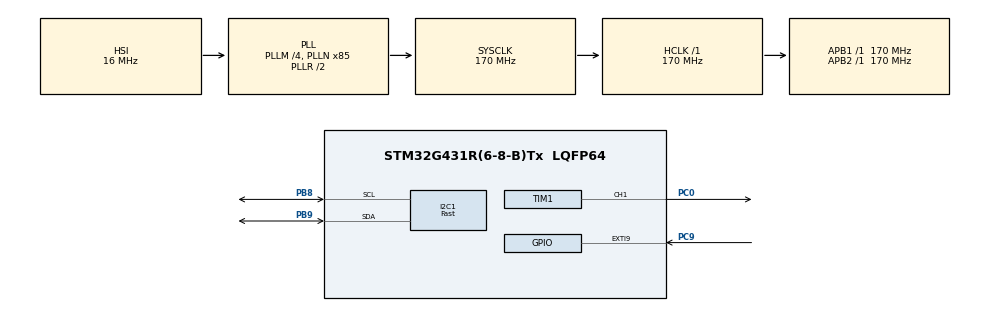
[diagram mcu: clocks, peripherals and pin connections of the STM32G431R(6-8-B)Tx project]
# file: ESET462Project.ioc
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Dma.I2C1_RX.0.Direction=DMA_PERIPH_TO_MEMORY
Dma.I2C1_RX.0.EventEnable=DISABLE
Dma.I2C1_RX.0.Instance=DMA1_Channel1
Dma.I2C1_RX.0.MemDataAlignment=DMA_MDATAALIGN_BYTE
Dma.I2C1_RX.0.MemInc=DMA_MINC_ENABLE
Dma.I2C1_RX.0.Mode=DMA_NORMAL
Dma.I2C1_RX.0.PeriphDataAlignment=DMA_PDATAALIGN_BYTE
Dma.I2C1_RX.0.PeriphInc=DMA_PINC_DISABLE
Dma.I2C1_RX.0.Polarity=HAL_DMAMUX_REQ_GEN_RISING
Dma.I2C1_RX.0.Priority=DMA_PRIORITY_LOW
Dma.I2C1_RX.0.RequestNumber=1
Dma.I2C1_RX.0.SignalID=NONE
Dma.I2C1_RX.0.SyncEnable=DISABLE
Dma.I2C1_RX.0.SyncPolarity=HAL_DMAMUX_SYNC_NO_EVENT
Dma.I2C1_RX.0.SyncRequestNumber=1
Dma.I2C1_RX.0.SyncSignalID=NONE
Dma.Request0=I2C1_RX
FREERTOS.Tasks01=defaultTask,24,128,StartDefaultTask,Default,NULL,Dynamic,NULL,NULL
FREERTOS.configCHECK_FOR_STACK_OVERFLOW=2
FREERTOS.configTOTAL_HEAP_SIZE=8192
FREERTOS.configUSE_MALLOC_FAILED_HOOK=1
I2C1.I2C_Speed_Mode=I2C_Fast
I2C1.Timing=0x40621236
Mcu.Family=STM32G4
Mcu.Name=STM32G431R(6-8-B)Tx
Mcu.Package=LQFP64
NUCLEO-G431RB.BUTTON=1
NUCLEO-G431RB.LD1=true
NUCLEO-G431RB.VCP=true
NVIC.DMA1_Channel1_IRQn=true\:5\:0\:false\:false\:true\:true\:false\:true\:true
NVIC.EXTI15_10_IRQn=true\:5\:0\:false\:false\:true\:true\:false\:true\:true
NVIC.EXTI9_5_IRQn=true\:5\:0\:false\:false\:true\:true\:true\:true\:true
NVIC.I2C1_ER_IRQn=true\:5\:0\:false\:false\:true\:true\:true\:true\:true
NVIC.I2C1_EV_IRQn=true\:5\:0\:false\:false\:true\:true\:true\:true\:true
NVIC.PriorityGroup=NVIC_PRIORITYGROUP_4
NVIC.TIM6_DAC_IRQn=true\:15\:0\:false\:false\:true\:false\:false\:true\:true
NVIC.TimeBase=TIM6_DAC_IRQn
NVIC.TimeBaseIP=TIM6
PA13.GPIO_Label=T_SWDIO
PA13.Mode=Serial_Wire
PA13.Signal=SYS_JTMS-SWDIO
PA14.GPIO_Label=T_SWCLK
PA14.Mode=Serial_Wire
PA14.Signal=SYS_JTCK-SWCLK
PA2.Signal=LPUART1_TX
PA3.Signal=LPUART1_RX
PB3.GPIO_Label=T_SWO
PB3.Signal=SYS_JTDO-SWO
PB8-BOOT0.Mode=I2C
PB8-BOOT0.Signal=I2C1_SCL
PB9.Mode=I2C
PB9.Signal=I2C1_SDA
PC0.Signal=S_TIM1_CH1
PC14-OSC32_IN.GPIO_Label=RCC_OSC32_OUT
PC14-OSC32_IN.Signal=RCC_OSC32_IN
PC15-OSC32_OUT.GPIO_Label=RCC_OSC32_OUT
PC15-OSC32_OUT.Signal=RCC_OSC32_OUT
PC9.Signal=GPXTI9
PF0-OSC_IN.GPIO_Label=RCC_OSC_IN
PF0-OSC_IN.Signal=RCC_OSC_IN
PF1-OSC_OUT.GPIO_Label=RCC_OSC_OUT
PF1-OSC_OUT.Signal=RCC_OSC_OUT
ProjectManager.HeapSize=0x200
ProjectManager.StackSize=0x400
ProjectManager.TargetToolchain=CMake
RCC.ADC12Freq_Value=170000000
RCC.AHBFreq_Value=170000000
RCC.APB1Freq_Value=170000000
RCC.APB1TimFreq_Value=170000000
RCC.APB2Freq_Value=170000000
RCC.APB2TimFreq_Value=170000000
RCC.CortexFreq_Value=170000000
RCC.EXTERNAL_CLOCK_VALUE=12288000
RCC.HCLKFreq_Value=170000000
RCC.HSE_VALUE=24000000
RCC.HSI48_VALUE=48000000
RCC.HSI_VALUE=16000000
RCC.LSE_VALUE=32768
RCC.PLLM=RCC_PLLM_DIV4
RCC.PLLN=85
RCC.RTCClockSelection=RCC_RTCCLKSOURCE_LSE
RCC.SYSCLKFreq_VALUE=170000000
RCC.SYSCLKSource=RCC_SYSCLKSOURCE_PLLCLK
RCC.USBFreq_Value=170000000
RCC.VCOOutputFreq_Value=340000000
SH.S_TIM1_CH1.0=TIM1_CH1,PWM Generation1 CH1
TIM1.AutoReloadPreload=TIM_AUTORELOAD_PRELOAD_ENABLE
TIM1.Channel-PWM\ Generation1\ CH1=TIM_CHANNEL_1
TIM1.PeriodNoDither=19999
TIM1.Prescaler=169
TIM1.PulseNoDither_1=1000
VP_FREERTOS_VS_CMSIS_V2.Mode=CMSIS_V2
VP_NUCLEO-G431RB_VS_BSP_COMMON.Mode=COMMON
VP_SYS_VS_DBSignals.Mode=DisableDeadBatterySignals
VP_SYS_VS_tim6.Mode=TIM6
VP_TIM1_VS_ClockSourceINT.Mode=Internal
board=NUCLEO-G431RB

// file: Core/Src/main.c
/* USER CODE BEGIN Header */
/**
  ******************************************************************************
  * @file           : main.c
  * @brief          : Main program body
  ******************************************************************************
  * @attention
  *
  * Copyright (c) 2026 STMicroelectronics.
  * All rights reserved.
  *
  * This software is licensed under terms that can be found in the LICENSE file
  * in the root directory of this software component.
  * If no LICENSE file comes with this software, it is provided AS-IS.
  *
  ******************************************************************************
  */
/* USER CODE END Header */
#include "main.h"
#include "cmsis_os.h"

/* USER CODE BEGIN Includes */
#include "controls.h"
/* USER CODE END Includes */

COM_InitTypeDef BspCOMInit;
I2C_HandleTypeDef hi2c1;
DMA_HandleTypeDef hdma_i2c1_rx;

TIM_HandleTypeDef htim1;

/* Definitions for defaultTask */
osThreadId_t defaultTaskHandle;
const osThreadAttr_t defaultTask_attributes = {
  .name = "defaultTask",
  .priority = (osPriority_t) osPriorityNormal,
  .stack_size = 128 * 4
};

void SystemClock_Config(void);
static void MX_GPIO_Init(void);
static void MX_DMA_Init(void);
static void MX_I2C1_Init(void);
static void MX_TIM1_Init(void);
void StartDefaultTask(void *argument);

int main(void)
{

  /* MCU Configuration--------------------------------------------------------*/

  /* Reset of all peripherals, Initializes the Flash interface and the Systick. */
  HAL_Init();

  /* Configure the system clock */
  SystemClock_Config();

  /* Initialize all configured peripherals */
  MX_GPIO_Init();
  MX_DMA_Init();
  MX_I2C1_Init();
  MX_TIM1_Init();
  /* USER CODE BEGIN 2 */
  Controls_Init(&hi2c1, &htim1, TIM_CHANNEL_1);
  /* USER CODE END 2 */

  /* Init scheduler */
  osKernelInitialize();

  /* Create the thread(s) */
  /* creation of defaultTask */
  defaultTaskHandle = osThreadNew(StartDefaultTask, NULL, &defaultTask_attributes);

  /* USER CODE BEGIN RTOS_THREADS */
  Controls_StartTask();
  /* USER CODE END RTOS_THREADS */

  /* Initialize leds */
  BSP_LED_Init(LED_GREEN);

  /* Initialize USER push-button, will be used to trigger an interrupt each time it's pressed.*/
  BSP_PB_Init(BUTTON_USER, BUTTON_MODE_EXTI);

  /* Initialize COM1 port (115200, 8 bits (7-bit data + 1 stop bit), no parity */
  BspCOMInit.BaudRate   = 115200;
  BspCOMInit.WordLength = COM_WORDLENGTH_8B;
  BspCOMInit.StopBits   = COM_STOPBITS_1;
  BspCOMInit.Parity     = COM_PARITY_NONE;
  BspCOMInit.HwFlowCtl  = COM_HWCONTROL_NONE;
  if (BSP_COM_Init(COM1, &BspCOMInit) != BSP_ERROR_NONE)
  {
    Error_Handler();
  }

  /* Start scheduler */
  osKernelStart();

  /* We should never get here as control is now taken by the scheduler */

  /* Infinite loop */
    while (1)
    {

    }
}

void SystemClock_Config(void)
{
  RCC_OscInitTypeDef RCC_OscInitStruct = {0};
  RCC_ClkInitTypeDef RCC_ClkInitStruct = {0};

  /** Configure the main internal regulator output voltage
  */
  HAL_PWREx_ControlVoltageScaling(PWR_REGULATOR_VOLTAGE_SCALE1_BOOST);

  /** Initializes the RCC Oscillators according to the specified parameters
  * in the RCC_OscInitTypeDef structure.
  */
  RCC_OscInitStruct.OscillatorType = RCC_OSCILLATORTYPE_HSI;
  RCC_OscInitStruct.HSIState = RCC_HSI_ON;
  RCC_OscInitStruct.HSICalibrationValue = RCC_HSICALIBRATION_DEFAULT;
  RCC_OscInitStruct.PLL.PLLState = RCC_PLL_ON;
  RCC_OscInitStruct.PLL.PLLSource = RCC_PLLSOURCE_HSI;
  RCC_OscInitStruct.PLL.PLLM = RCC_PLLM_DIV4;
  RCC_OscInitStruct.PLL.PLLN = 85;
  RCC_OscInitStruct.PLL.PLLP = RCC_PLLP_DIV2;
  RCC_OscInitStruct.PLL.PLLQ = RCC_PLLQ_DIV2;
  RCC_OscInitStruct.PLL.PLLR = RCC_PLLR_DIV2;
  if (HAL_RCC_OscConfig(&RCC_OscInitStruct) != HAL_OK)
  {
    Error_Handler();
  }

  /** Initializes the CPU, AHB and APB buses clocks
  */
  RCC_ClkInitStruct.ClockType = RCC_CLOCKTYPE_HCLK|RCC_CLOCKTYPE_SYSCLK
                              |RCC_CLOCKTYPE_PCLK1|RCC_CLOCKTYPE_PCLK2;
  RCC_ClkInitStruct.SYSCLKSource = RCC_SYSCLKSOURCE_PLLCLK;
  RCC_ClkInitStruct.AHBCLKDivider = RCC_SYSCLK_DIV1;
  RCC_ClkInitStruct.APB1CLKDivider = RCC_HCLK_DIV1;
  RCC_ClkInitStruct.APB2CLKDivider = RCC_HCLK_DIV1;

  if (HAL_RCC_ClockConfig(&RCC_ClkInitStruct, FLASH_LATENCY_4) != HAL_OK)
  {
    Error_Handler();
  }
}

static void MX_I2C1_Init(void)
{

  hi2c1.Instance = I2C1;
  hi2c1.Init.Timing = 0x40621236;
  hi2c1.Init.OwnAddress1 = 0;
  hi2c1.Init.AddressingMode = I2C_ADDRESSINGMODE_7BIT;
  hi2c1.Init.DualAddressMode = I2C_DUALADDRESS_DISABLE;
  hi2c1.Init.OwnAddress2 = 0;
  hi2c1.Init.OwnAddress2Masks = I2C_OA2_NOMASK;
  hi2c1.Init.GeneralCallMode = I2C_GENERALCALL_DISABLE;
  hi2c1.Init.NoStretchMode = I2C_NOSTRETCH_DISABLE;
  if (HAL_I2C_Init(&hi2c1) != HAL_OK)
  {
    Error_Handler();
  }

  /** Configure Analogue filter
  */
  if (HAL_I2CEx_ConfigAnalogFilter(&hi2c1, I2C_ANALOGFILTER_ENABLE) != HAL_OK)
  {
    Error_Handler();
  }

  /** Configure Digital filter
  */
  if (HAL_I2CEx_ConfigDigitalFilter(&hi2c1, 0) != HAL_OK)
  {
    Error_Handler();
  }

}

static void MX_TIM1_Init(void)
{

  TIM_ClockConfigTypeDef sClockSourceConfig = {0};
  TIM_MasterConfigTypeDef sMasterConfig = {0};
  TIM_OC_InitTypeDef sConfigOC = {0};
  TIM_BreakDeadTimeConfigTypeDef sBreakDeadTimeConfig = {0};

  htim1.Instance = TIM1;
  htim1.Init.Prescaler = 169;
  htim1.Init.CounterMode = TIM_COUNTERMODE_UP;
  htim1.Init.Period = 19999;
  htim1.Init.ClockDivision = TIM_CLOCKDIVISION_DIV1;
  htim1.Init.RepetitionCounter = 0;
  htim1.Init.AutoReloadPreload = TIM_AUTORELOAD_PRELOAD_ENABLE;
  if (HAL_TIM_Base_Init(&htim1) != HAL_OK)
  {
    Error_Handler();
  }
  sClockSourceConfig.ClockSource = TIM_CLOCKSOURCE_INTERNAL;
  if (HAL_TIM_ConfigClockSource(&htim1, &sClockSourceConfig) != HAL_OK)
  {
    Error_Handler();
  }
  if (HAL_TIM_PWM_Init(&htim1) != HAL_OK)
  {
    Error_Handler();
  }
  sMasterConfig.MasterOutputTrigger = TIM_TRGO_RESET;
  sMasterConfig.MasterOutputTrigger2 = TIM_TRGO2_RESET;
  sMasterConfig.MasterSlaveMode = TIM_MASTERSLAVEMODE_DISABLE;
  if (HAL_TIMEx_MasterConfigSynchronization(&htim1, &sMasterConfig) != HAL_OK)
  {
    Error_Handler();
  }
  sConfigOC.OCMode = TIM_OCMODE_PWM1;
  sConfigOC.Pulse = 1000;
  sConfigOC.OCPolarity = TIM_OCPOLARITY_HIGH;
  sConfigOC.OCNPolarity = TIM_OCNPOLARITY_HIGH;
  sConfigOC.OCFastMode = TIM_OCFAST_DISABLE;
  sConfigOC.OCIdleState = TIM_OCIDLESTATE_RESET;
  sConfigOC.OCNIdleState = TIM_OCNIDLESTATE_RESET;
  if (HAL_TIM_PWM_ConfigChannel(&htim1, &sConfigOC, TIM_CHANNEL_1) != HAL_OK)
  {
    Error_Handler();
  }
  sBreakDeadTimeConfig.OffStateRunMode = TIM_OSSR_DISABLE;
  sBreakDeadTimeConfig.OffStateIDLEMode = TIM_OSSI_DISABLE;
  sBreakDeadTimeConfig.LockLevel = TIM_LOCKLEVEL_OFF;
  sBreakDeadTimeConfig.DeadTime = 0;
  sBreakDeadTimeConfig.BreakState = TIM_BREAK_DISABLE;
  sBreakDeadTimeConfig.BreakPolarity = TIM_BREAKPOLARITY_HIGH;
  sBreakDeadTimeConfig.BreakFilter = 0;
  sBreakDeadTimeConfig.BreakAFMode = TIM_BREAK_AFMODE_INPUT;
  sBreakDeadTimeConfig.Break2State = TIM_BREAK2_DISABLE;
  sBreakDeadTimeConfig.Break2Polarity = TIM_BREAK2POLARITY_HIGH;
  sBreakDeadTimeConfig.Break2Filter = 0;
  sBreakDeadTimeConfig.Break2AFMode = TIM_BREAK_AFMODE_INPUT;
  sBreakDeadTimeConfig.AutomaticOutput = TIM_AUTOMATICOUTPUT_DISABLE;
  if (HAL_TIMEx_ConfigBreakDeadTime(&htim1, &sBreakDeadTimeConfig) != HAL_OK)
  {
    Error_Handler();
  }
  HAL_TIM_MspPostInit(&htim1);

}

static void MX_DMA_Init(void)
{

  /* DMA controller clock enable */
  __HAL_RCC_DMAMUX1_CLK_ENABLE();
  __HAL_RCC_DMA1_CLK_ENABLE();

  /* DMA interrupt init */
  /* DMA1_Channel1_IRQn interrupt configuration */
  HAL_NVIC_SetPriority(DMA1_Channel1_IRQn, 5, 0);
  HAL_NVIC_EnableIRQ(DMA1_Channel1_IRQn);

}

static void MX_GPIO_Init(void)
{
  GPIO_InitTypeDef GPIO_InitStruct = {0};

  /* GPIO Ports Clock Enable */
  __HAL_RCC_GPIOC_CLK_ENABLE();
  __HAL_RCC_GPIOF_CLK_ENABLE();
  __HAL_RCC_GPIOA_CLK_ENABLE();
  __HAL_RCC_GPIOB_CLK_ENABLE();

  /*Configure GPIO pin : PC9 */
  GPIO_InitStruct.Pin = GPIO_PIN_9;
  GPIO_InitStruct.Mode = GPIO_MODE_IT_RISING;
  GPIO_InitStruct.Pull = GPIO_NOPULL;
  HAL_GPIO_Init(GPIOC, &GPIO_InitStruct);

  /* EXTI interrupt init*/
  HAL_NVIC_SetPriority(EXTI9_5_IRQn, 5, 0);
  HAL_NVIC_EnableIRQ(EXTI9_5_IRQn);

}

void StartDefaultTask(void *argument)
{
  /* USER CODE BEGIN 5 */
    /* Heartbeat */
    for (;;)
    {
        HAL_GPIO_TogglePin(LED2_GPIO_PORT, LED2_PIN);
        osDelay(500);
    }
  /* USER CODE END 5 */
}

void HAL_TIM_PeriodElapsedCallback(TIM_HandleTypeDef *htim)
{
  if (htim->Instance == TIM6)
  {
    HAL_IncTick();
  }
}

void Error_Handler(void)
{
    __disable_irq();
    while (1)
    {
    }
}
